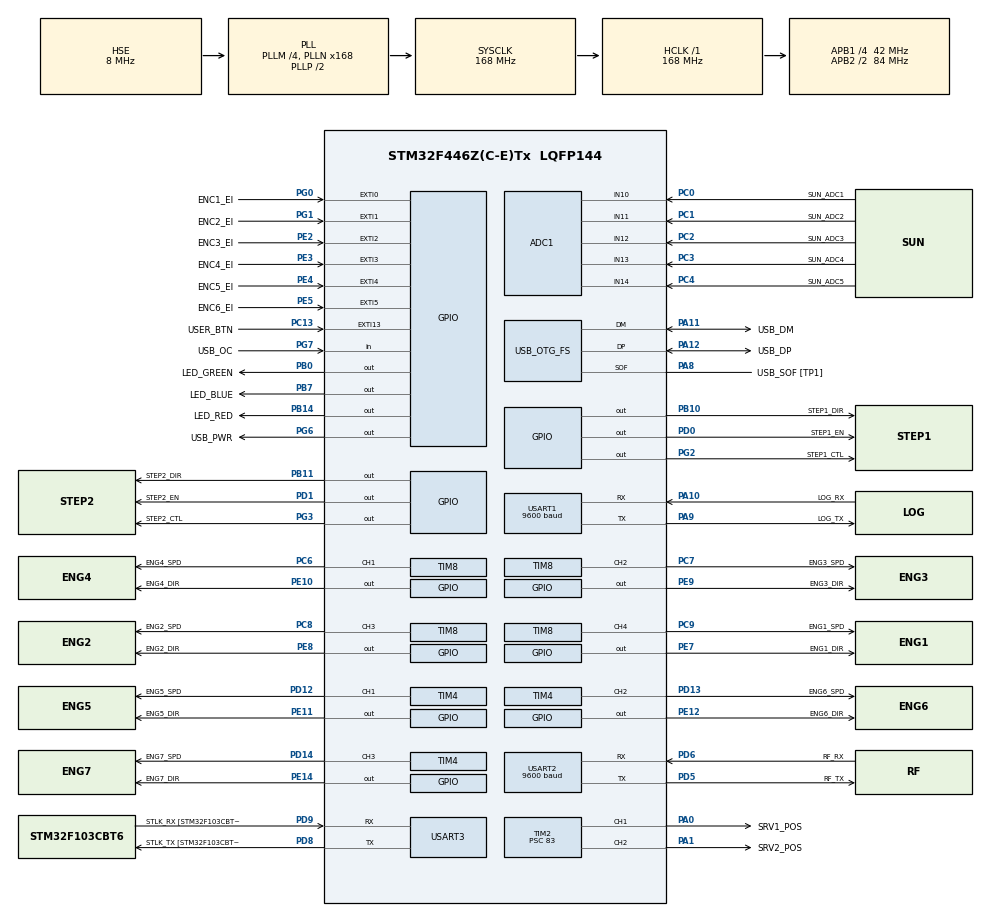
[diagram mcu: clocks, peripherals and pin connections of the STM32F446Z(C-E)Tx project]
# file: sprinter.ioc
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ADC1.Channel-0\#ChannelRegularConversion=ADC_CHANNEL_10
ADC1.ContinuousConvMode=ENABLE
ADC1.NbrOfConversion=1
ADC1.NbrOfConversionFlag=1
ADC1.Rank-0\#ChannelRegularConversion=1
ADC1.SamplingTime-0\#ChannelRegularConversion=ADC_SAMPLETIME_3CYCLES
ADC1.master=1
Mcu.Family=STM32F4
Mcu.Name=STM32F446Z(C-E)Tx
Mcu.Package=LQFP144
NVIC.EXTI0_IRQn=true\:0\:0\:false\:false\:true\:true\:true
NVIC.EXTI15_10_IRQn=true\:0\:0\:false\:false\:true\:true\:true
NVIC.EXTI1_IRQn=true\:0\:0\:false\:false\:true\:true\:true
NVIC.EXTI2_IRQn=true\:0\:0\:false\:false\:true\:true\:true
NVIC.EXTI3_IRQn=true\:0\:0\:false\:false\:true\:true\:true
NVIC.EXTI4_IRQn=true\:0\:0\:false\:false\:true\:true\:true
NVIC.EXTI9_5_IRQn=true\:0\:0\:false\:false\:true\:true\:true
NVIC.PriorityGroup=NVIC_PRIORITYGROUP_4
NVIC.USART1_IRQn=true\:0\:0\:false\:false\:true\:true\:true
NVIC.USART2_IRQn=true\:0\:0\:false\:false\:true\:true\:true
PA0-WKUP.GPIO_Label=SRV1_POS
PA0-WKUP.Signal=S_TIM2_CH1_ETR
PA1.GPIO_Label=SRV2_POS
PA1.Signal=S_TIM2_CH2
PA10.GPIO_Label=LOG_RX
PA10.Mode=Asynchronous
PA10.Signal=USART1_RX
PA11.GPIO_Label=USB_DM
PA11.Mode=Device_Only
PA11.Signal=USB_OTG_FS_DM
PA12.GPIO_Label=USB_DP
PA12.Mode=Device_Only
PA12.Signal=USB_OTG_FS_DP
PA13.GPIO_Label=TMS
PA13.Mode=Serial_Wire
PA13.Signal=SYS_JTMS-SWDIO
PA14.GPIO_Label=TCK
PA14.Mode=Serial_Wire
PA14.Signal=SYS_JTCK-SWCLK
PA8.GPIO_Label=USB_SOF [TP1]
PA8.Mode=Activate_SOF_FS
PA8.Signal=USB_OTG_FS_SOF
PA9.GPIO_Label=LOG_TX
PA9.Mode=Asynchronous
PA9.Signal=USART1_TX
PB0.GPIO_Label=LED_GREEN
PB0.Signal=GPIO_Output
PB10.GPIO_Label=STEP1_DIR
PB10.Signal=GPIO_Output
PB11.GPIO_Label=STEP2_DIR
PB11.Signal=GPIO_Output
PB14.GPIO_Label=LED_RED
PB14.Signal=GPIO_Output
PB7.GPIO_Label=LED_BLUE
PB7.Signal=GPIO_Output
PC0.GPIO_Label=SUN_ADC1
PC0.Signal=ADCx_IN10
PC1.GPIO_Label=SUN_ADC2
PC1.Signal=ADCx_IN11
PC13.GPIO_Label=USER_BTN
PC13.Signal=GPXTI13
PC14-OSC32_IN.GPIO_Label=OSC32_IN
PC14-OSC32_IN.Mode=LSE-External-Oscillator
PC14-OSC32_IN.Signal=RCC_OSC32_IN
PC15-OSC32_OUT.GPIO_Label=OSC32_OUT
PC15-OSC32_OUT.Mode=LSE-External-Oscillator
PC15-OSC32_OUT.Signal=RCC_OSC32_OUT
PC2.GPIO_Label=SUN_ADC3
PC2.Signal=ADCx_IN12
PC3.GPIO_Label=SUN_ADC4
PC3.Signal=ADCx_IN13
PC4.GPIO_Label=SUN_ADC5
PC4.Signal=ADCx_IN14
PC6.GPIO_Label=ENG4_SPD
PC6.Signal=S_TIM8_CH1
PC7.GPIO_Label=ENG3_SPD
PC7.Signal=S_TIM8_CH2
PC8.GPIO_Label=ENG2_SPD
PC8.Signal=S_TIM8_CH3
PC9.GPIO_Label=ENG1_SPD
PC9.Signal=S_TIM8_CH4
PD0.GPIO_Label=STEP1_EN
PD0.Signal=GPIO_Output
PD1.GPIO_Label=STEP2_EN
PD1.Signal=GPIO_Output
PD12.GPIO_Label=ENG5_SPD
PD12.Signal=S_TIM4_CH1
PD13.GPIO_Label=ENG6_SPD
PD13.Signal=S_TIM4_CH2
PD14.GPIO_Label=ENG7_SPD
PD14.Signal=S_TIM4_CH3
PD5.GPIO_Label=RF_TX
PD5.Mode=Asynchronous
PD5.Signal=USART2_TX
PD6.GPIO_Label=RF_RX
PD6.Mode=Asynchronous
PD6.Signal=USART2_RX
PD8.GPIO_Label=STLK_TX [STM32F103CBT6_PA3]
PD8.Mode=Asynchronous
PD8.Signal=USART3_TX
PD9.GPIO_Label=STLK_RX [STM32F103CBT6_PA2]
PD9.Mode=Asynchronous
PD9.Signal=USART3_RX
PE10.GPIO_Label=ENG4_DIR
PE10.Signal=GPIO_Output
PE11.GPIO_Label=ENG5_DIR
PE11.Signal=GPIO_Output
PE12.GPIO_Label=ENG6_DIR
PE12.Signal=GPIO_Output
PE14.GPIO_Label=ENG7_DIR
PE14.Signal=GPIO_Output
PE2.GPIO_Label=ENC3_EI
PE2.GPIO_ModeDefaultEXTI=GPIO_MODE_IT_RISING_FALLING
PE2.GPIO_PuPd=GPIO_PULLDOWN
PE2.Signal=GPXTI2
PE3.GPIO_Label=ENC4_EI
PE3.GPIO_ModeDefaultEXTI=GPIO_MODE_IT_RISING_FALLING
PE3.GPIO_PuPd=GPIO_PULLDOWN
PE3.Signal=GPXTI3
PE4.GPIO_Label=ENC5_EI
PE4.GPIO_ModeDefaultEXTI=GPIO_MODE_IT_RISING_FALLING
PE4.GPIO_PuPd=GPIO_PULLDOWN
PE4.Signal=GPXTI4
PE5.GPIO_Label=ENC6_EI
PE5.GPIO_ModeDefaultEXTI=GPIO_MODE_IT_RISING_FALLING
PE5.GPIO_PuPd=GPIO_PULLDOWN
PE5.Signal=GPXTI5
PE7.GPIO_Label=ENG1_DIR
PE7.Signal=GPIO_Output
PE8.GPIO_Label=ENG2_DIR
PE8.Signal=GPIO_Output
PE9.GPIO_Label=ENG3_DIR
PE9.Signal=GPIO_Output
PG0.GPIO_Label=ENC1_EI
PG0.GPIO_ModeDefaultEXTI=GPIO_MODE_IT_RISING_FALLING
PG0.GPIO_PuPd=GPIO_PULLDOWN
PG0.Signal=GPXTI0
PG1.GPIO_Label=ENC2_EI
PG1.GPIO_ModeDefaultEXTI=GPIO_MODE_IT_RISING_FALLING
PG1.GPIO_PuPd=GPIO_PULLDOWN
PG1.Signal=GPXTI1
PG2.GPIO_Label=STEP1_CTL
PG2.Signal=GPIO_Output
PG3.GPIO_Label=STEP2_CTL
PG3.Signal=GPIO_Output
PG6.GPIO_Label=USB_PWR
PG6.Signal=GPIO_Output
PG7.GPIO_Label=USB_OC
PG7.Signal=GPIO_Input
PH0-OSC_IN.GPIO_Label=MCO [STM32F103CBT6_PA8]
PH0-OSC_IN.Mode=HSE-External-Clock-Source
PH0-OSC_IN.Signal=RCC_OSC_IN
PH1-OSC_OUT.GPIO_Label=OSC_OUT
PH1-OSC_OUT.Mode=HSE-External-Clock-Source
PH1-OSC_OUT.Signal=RCC_OSC_OUT
ProjectManager.HeapSize=0x200
ProjectManager.StackSize=0x400
ProjectManager.TargetToolchain=SW4STM32
RCC.48MHZClocksFreq_Value=24000000
RCC.AHBFreq_Value=168000000
RCC.APB1CLKDivider=RCC_HCLK_DIV4
RCC.APB1Freq_Value=42000000
RCC.APB1TimFreq_Value=84000000
RCC.APB2CLKDivider=RCC_HCLK_DIV2
RCC.APB2Freq_Value=84000000
RCC.APB2TimFreq_Value=168000000
RCC.CortexFreq_Value=168000000
RCC.HCLKFreq_Value=168000000
RCC.HSE_VALUE=8000000
RCC.HSI_VALUE=16000000
RCC.PLLM=4
RCC.PLLMUL=RCC_PLL_MUL9
RCC.PLLN=168
RCC.PLLQ=7
RCC.PRESCALERUSB=RCC_USBCLKSOURCE_PLL_DIV1_5
RCC.SYSCLKFreq_VALUE=168000000
RCC.SYSCLKSource=RCC_SYSCLKSOURCE_PLLCLK
RCC.SYSCLKSourceVirtual=RCC_SYSCLKSOURCE_PLLCLK
RCC.USBFreq_Value=48000000
RCC.VCOOutputFreq_Value=336000000
SH.ADCx_IN10.0=ADC1_IN10,IN10
SH.ADCx_IN11.0=ADC1_IN11,IN11
SH.ADCx_IN12.0=ADC1_IN12,IN12
SH.ADCx_IN13.0=ADC1_IN13,IN13
SH.ADCx_IN14.0=ADC1_IN14,IN14
SH.S_TIM2_CH1_ETR.0=TIM2_CH1,PWM Generation1 CH1
SH.S_TIM2_CH2.0=TIM2_CH2,PWM Generation2 CH2
SH.S_TIM4_CH1.0=TIM4_CH1,PWM Generation1 CH1
SH.S_TIM4_CH2.0=TIM4_CH2,PWM Generation2 CH2
SH.S_TIM4_CH3.0=TIM4_CH3,PWM Generation3 CH3
SH.S_TIM8_CH1.0=TIM8_CH1,PWM Generation1 CH1
SH.S_TIM8_CH2.0=TIM8_CH2,PWM Generation2 CH2
SH.S_TIM8_CH3.0=TIM8_CH3,PWM Generation3 CH3
SH.S_TIM8_CH4.0=TIM8_CH4,PWM Generation4 CH4
TIM2.Channel-PWM\ Generation1\ CH1=TIM_CHANNEL_1
TIM2.Channel-PWM\ Generation2\ CH2=TIM_CHANNEL_2
TIM2.OCMode_PWM-PWM\ Generation1\ CH1=TIM_OCMODE_PWM2
TIM2.OCMode_PWM-PWM\ Generation2\ CH2=TIM_OCMODE_PWM2
TIM2.OCPolarity_2=TIM_OCPOLARITY_LOW
TIM2.Period=19999
TIM2.Prescaler=83
TIM2.Pulse-PWM\ Generation1\ CH1=3360000
TIM2.Pulse-PWM\ Generation2\ CH2=3360000
TIM4.Channel-PWM\ Generation1\ CH1=TIM_CHANNEL_1
TIM4.Channel-PWM\ Generation2\ CH2=TIM_CHANNEL_2
TIM4.Channel-PWM\ Generation3\ CH3=TIM_CHANNEL_3
TIM4.OCMode_PWM-PWM\ Generation1\ CH1=TIM_OCMODE_PWM2
TIM4.OCMode_PWM-PWM\ Generation2\ CH2=TIM_OCMODE_PWM2
TIM4.OCMode_PWM-PWM\ Generation3\ CH3=TIM_OCMODE_PWM2
TIM4.OCPolarity_1=TIM_OCPOLARITY_LOW
TIM4.OCPolarity_2=TIM_OCPOLARITY_LOW
TIM4.OCPolarity_3=TIM_OCPOLARITY_LOW
TIM4.Period=99
TIM4.Prescaler=1049
TIM4.Pulse-PWM\ Generation1\ CH1=210000
TIM4.Pulse-PWM\ Generation2\ CH2=210000
TIM4.Pulse-PWM\ Generation3\ CH3=210000
TIM8.Channel-PWM\ Generation1\ CH1=TIM_CHANNEL_1
TIM8.Channel-PWM\ Generation2\ CH2=TIM_CHANNEL_2
TIM8.Channel-PWM\ Generation3\ CH3=TIM_CHANNEL_3
TIM8.Channel-PWM\ Generation4\ CH4=TIM_CHANNEL_4
TIM8.OCIdleState_1=TIM_OCIDLESTATE_SET
TIM8.OCIdleState_2=TIM_OCIDLESTATE_SET
TIM8.OCIdleState_3=TIM_OCIDLESTATE_SET
TIM8.OCIdleState_4=TIM_OCIDLESTATE_SET
TIM8.OCMode_PWM-PWM\ Generation1\ CH1=TIM_OCMODE_PWM2
TIM8.OCMode_PWM-PWM\ Generation2\ CH2=TIM_OCMODE_PWM2
TIM8.OCMode_PWM-PWM\ Generation3\ CH3=TIM_OCMODE_PWM2
TIM8.OCMode_PWM-PWM\ Generation4\ CH4=TIM_OCMODE_PWM2
TIM8.OCPolarity_1=TIM_OCPOLARITY_LOW
TIM8.OCPolarity_2=TIM_OCPOLARITY_LOW
TIM8.OCPolarity_3=TIM_OCPOLARITY_LOW
TIM8.OCPolarity_4=TIM_OCPOLARITY_LOW
TIM8.Period=99
TIM8.Prescaler=2099
TIM8.Pulse-PWM\ Generation1\ CH1=210000
TIM8.Pulse-PWM\ Generation2\ CH2=210000
TIM8.Pulse-PWM\ Generation3\ CH3=210000
TIM8.Pulse-PWM\ Generation4\ CH4=210000
USART1.BaudRate=9600
USART1.VirtualMode=VM_ASYNC
USART2.BaudRate=9600
USART2.VirtualMode=VM_ASYNC
USART3.VirtualMode=VM_ASYNC
USB_OTG_FS.VirtualMode=Device_Only
VP_TIM2_VS_ClockSourceINT.Mode=Internal
VP_TIM4_VS_ClockSourceINT.Mode=Internal
VP_TIM8_VS_ClockSourceINT.Mode=Internal
board=NUCLEO-F446ZE

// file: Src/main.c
/* USER CODE BEGIN Header */
/**
  ******************************************************************************
  * @file           : main.c
  * @brief          : Main program body
  ******************************************************************************
  * @attention
  *
  * <h2><center>&copy; Copyright (c) 2019 STMicroelectronics.
  * All rights reserved.</center></h2>
  *
  * This software component is licensed by ST under BSD 3-Clause license,
  * the "License"; You may not use this file except in compliance with the
  * License. You may obtain a copy of the License at:
  *                        opensource.org/licenses/BSD-3-Clause
  *
  ******************************************************************************
  */
/* USER CODE END Header */

#include "main.h"

/* USER CODE BEGIN Includes */
#include "sprinter/run.h"
/* USER CODE END Includes */

ADC_HandleTypeDef hadc1;

TIM_HandleTypeDef htim2;
TIM_HandleTypeDef htim4;
TIM_HandleTypeDef htim8;

UART_HandleTypeDef huart1;
UART_HandleTypeDef huart2;
UART_HandleTypeDef huart3;

PCD_HandleTypeDef hpcd_USB_OTG_FS;

void SystemClock_Config(void);
static void MX_GPIO_Init(void);
static void MX_USART3_UART_Init(void);
static void MX_USB_OTG_FS_PCD_Init(void);
static void MX_USART2_UART_Init(void);
static void MX_TIM8_Init(void);
static void MX_USART1_UART_Init(void);
static void MX_TIM4_Init(void);
static void MX_ADC1_Init(void);
static void MX_TIM2_Init(void);

int main(void)
{

  /* MCU Configuration--------------------------------------------------------*/

  /* Reset of all peripherals, Initializes the Flash interface and the Systick. */
  HAL_Init();

  /* Configure the system clock */
  SystemClock_Config();

  /* Initialize all configured peripherals */
  MX_GPIO_Init();
  MX_USART3_UART_Init();
  MX_USB_OTG_FS_PCD_Init();
  MX_USART2_UART_Init();
  MX_TIM8_Init();
  MX_USART1_UART_Init();
  MX_TIM4_Init();
  MX_ADC1_Init();
  MX_TIM2_Init();

  /* Infinite loop */
  /* USER CODE BEGIN WHILE */

  // no return
  run();

    /* USER CODE END WHILE */

}

void SystemClock_Config(void)
{
  RCC_OscInitTypeDef RCC_OscInitStruct = {0};
  RCC_ClkInitTypeDef RCC_ClkInitStruct = {0};
  RCC_PeriphCLKInitTypeDef PeriphClkInitStruct = {0};

  /** Configure the main internal regulator output voltage
  */
  __HAL_RCC_PWR_CLK_ENABLE();
  __HAL_PWR_VOLTAGESCALING_CONFIG(PWR_REGULATOR_VOLTAGE_SCALE1);
  /** Initializes the CPU, AHB and APB busses clocks
  */
  RCC_OscInitStruct.OscillatorType = RCC_OSCILLATORTYPE_HSE;
  RCC_OscInitStruct.HSEState = RCC_HSE_BYPASS;
  RCC_OscInitStruct.PLL.PLLState = RCC_PLL_ON;
  RCC_OscInitStruct.PLL.PLLSource = RCC_PLLSOURCE_HSE;
  RCC_OscInitStruct.PLL.PLLM = 4;
  RCC_OscInitStruct.PLL.PLLN = 168;
  RCC_OscInitStruct.PLL.PLLP = RCC_PLLP_DIV2;
  RCC_OscInitStruct.PLL.PLLQ = 7;
  RCC_OscInitStruct.PLL.PLLR = 2;
  if (HAL_RCC_OscConfig(&RCC_OscInitStruct) != HAL_OK)
  {
    Error_Handler();
  }
  /** Initializes the CPU, AHB and APB busses clocks
  */
  RCC_ClkInitStruct.ClockType = RCC_CLOCKTYPE_HCLK|RCC_CLOCKTYPE_SYSCLK
                              |RCC_CLOCKTYPE_PCLK1|RCC_CLOCKTYPE_PCLK2;
  RCC_ClkInitStruct.SYSCLKSource = RCC_SYSCLKSOURCE_PLLCLK;
  RCC_ClkInitStruct.AHBCLKDivider = RCC_SYSCLK_DIV1;
  RCC_ClkInitStruct.APB1CLKDivider = RCC_HCLK_DIV4;
  RCC_ClkInitStruct.APB2CLKDivider = RCC_HCLK_DIV2;

  if (HAL_RCC_ClockConfig(&RCC_ClkInitStruct, FLASH_LATENCY_5) != HAL_OK)
  {
    Error_Handler();
  }
  PeriphClkInitStruct.PeriphClockSelection = RCC_PERIPHCLK_CLK48;
  PeriphClkInitStruct.Clk48ClockSelection = RCC_CLK48CLKSOURCE_PLLQ;
  if (HAL_RCCEx_PeriphCLKConfig(&PeriphClkInitStruct) != HAL_OK)
  {
    Error_Handler();
  }
}

static void MX_ADC1_Init(void)
{

  ADC_ChannelConfTypeDef sConfig = {0};

  /** Configure the global features of the ADC (Clock, Resolution, Data Alignment and number of conversion)
  */
  hadc1.Instance = ADC1;
  hadc1.Init.ClockPrescaler = ADC_CLOCK_SYNC_PCLK_DIV4;
  hadc1.Init.Resolution = ADC_RESOLUTION_12B;
  hadc1.Init.ScanConvMode = DISABLE;
  hadc1.Init.ContinuousConvMode = ENABLE;
  hadc1.Init.DiscontinuousConvMode = DISABLE;
  hadc1.Init.ExternalTrigConvEdge = ADC_EXTERNALTRIGCONVEDGE_NONE;
  hadc1.Init.ExternalTrigConv = ADC_SOFTWARE_START;
  hadc1.Init.DataAlign = ADC_DATAALIGN_RIGHT;
  hadc1.Init.NbrOfConversion = 1;
  hadc1.Init.DMAContinuousRequests = DISABLE;
  hadc1.Init.EOCSelection = ADC_EOC_SINGLE_CONV;
  if (HAL_ADC_Init(&hadc1) != HAL_OK)
  {
    Error_Handler();
  }
  /** Configure for the selected ADC regular channel its corresponding rank in the sequencer and its sample time.
  */
  sConfig.Channel = ADC_CHANNEL_10;
  sConfig.Rank = 1;
  sConfig.SamplingTime = ADC_SAMPLETIME_3CYCLES;
  if (HAL_ADC_ConfigChannel(&hadc1, &sConfig) != HAL_OK)
  {
    Error_Handler();
  }

}

static void MX_TIM2_Init(void)
{

  TIM_ClockConfigTypeDef sClockSourceConfig = {0};
  TIM_MasterConfigTypeDef sMasterConfig = {0};
  TIM_OC_InitTypeDef sConfigOC = {0};

  /* USER CODE BEGIN TIM2_Init 1 */

  sConfigOC.OCNPolarity = TIM_OCNPOLARITY_HIGH;
  sConfigOC.OCIdleState = TIM_OCIDLESTATE_SET;
  sConfigOC.OCNIdleState = TIM_OCNIDLESTATE_RESET;

  /* USER CODE END TIM2_Init 1 */
  htim2.Instance = TIM2;
  htim2.Init.Prescaler = 83;
  htim2.Init.CounterMode = TIM_COUNTERMODE_UP;
  htim2.Init.Period = 19999;
  htim2.Init.ClockDivision = TIM_CLOCKDIVISION_DIV1;
  htim2.Init.AutoReloadPreload = TIM_AUTORELOAD_PRELOAD_DISABLE;
  if (HAL_TIM_Base_Init(&htim2) != HAL_OK)
  {
    Error_Handler();
  }
  sClockSourceConfig.ClockSource = TIM_CLOCKSOURCE_INTERNAL;
  if (HAL_TIM_ConfigClockSource(&htim2, &sClockSourceConfig) != HAL_OK)
  {
    Error_Handler();
  }
  if (HAL_TIM_PWM_Init(&htim2) != HAL_OK)
  {
    Error_Handler();
  }
  sMasterConfig.MasterOutputTrigger = TIM_TRGO_RESET;
  sMasterConfig.MasterSlaveMode = TIM_MASTERSLAVEMODE_DISABLE;
  if (HAL_TIMEx_MasterConfigSynchronization(&htim2, &sMasterConfig) != HAL_OK)
  {
    Error_Handler();
  }
  sConfigOC.OCMode = TIM_OCMODE_PWM2;
  sConfigOC.Pulse = 3360000;
  sConfigOC.OCPolarity = TIM_OCPOLARITY_HIGH;
  sConfigOC.OCFastMode = TIM_OCFAST_DISABLE;
  if (HAL_TIM_PWM_ConfigChannel(&htim2, &sConfigOC, TIM_CHANNEL_1) != HAL_OK)
  {
    Error_Handler();
  }
  sConfigOC.OCPolarity = TIM_OCPOLARITY_LOW;
  if (HAL_TIM_PWM_ConfigChannel(&htim2, &sConfigOC, TIM_CHANNEL_2) != HAL_OK)
  {
    Error_Handler();
  }
  HAL_TIM_MspPostInit(&htim2);

}

static void MX_TIM4_Init(void)
{

  TIM_ClockConfigTypeDef sClockSourceConfig = {0};
  TIM_MasterConfigTypeDef sMasterConfig = {0};
  TIM_OC_InitTypeDef sConfigOC = {0};

  /* USER CODE BEGIN TIM4_Init 1 */

  sConfigOC.OCNPolarity = TIM_OCNPOLARITY_HIGH;
  sConfigOC.OCIdleState = TIM_OCIDLESTATE_SET;
  sConfigOC.OCNIdleState = TIM_OCNIDLESTATE_RESET;

  /* USER CODE END TIM4_Init 1 */
  htim4.Instance = TIM4;
  htim4.Init.Prescaler = 1049;
  htim4.Init.CounterMode = TIM_COUNTERMODE_UP;
  htim4.Init.Period = 99;
  htim4.Init.ClockDivision = TIM_CLOCKDIVISION_DIV1;
  htim4.Init.AutoReloadPreload = TIM_AUTORELOAD_PRELOAD_DISABLE;
  if (HAL_TIM_Base_Init(&htim4) != HAL_OK)
  {
    Error_Handler();
  }
  sClockSourceConfig.ClockSource = TIM_CLOCKSOURCE_INTERNAL;
  if (HAL_TIM_ConfigClockSource(&htim4, &sClockSourceConfig) != HAL_OK)
  {
    Error_Handler();
  }
  if (HAL_TIM_PWM_Init(&htim4) != HAL_OK)
  {
    Error_Handler();
  }
  sMasterConfig.MasterOutputTrigger = TIM_TRGO_RESET;
  sMasterConfig.MasterSlaveMode = TIM_MASTERSLAVEMODE_DISABLE;
  if (HAL_TIMEx_MasterConfigSynchronization(&htim4, &sMasterConfig) != HAL_OK)
  {
    Error_Handler();
  }
  sConfigOC.OCMode = TIM_OCMODE_PWM2;
  sConfigOC.Pulse = 210000;
  sConfigOC.OCPolarity = TIM_OCPOLARITY_LOW;
  sConfigOC.OCFastMode = TIM_OCFAST_DISABLE;
  if (HAL_TIM_PWM_ConfigChannel(&htim4, &sConfigOC, TIM_CHANNEL_1) != HAL_OK)
  {
    Error_Handler();
  }
  if (HAL_TIM_PWM_ConfigChannel(&htim4, &sConfigOC, TIM_CHANNEL_2) != HAL_OK)
  {
    Error_Handler();
  }
  if (HAL_TIM_PWM_ConfigChannel(&htim4, &sConfigOC, TIM_CHANNEL_3) != HAL_OK)
  {
    Error_Handler();
  }
  /* USER CODE BEGIN TIM4_Init 2 */

	htim2.Instance->CCR1 = htim2.Instance->CCR2 = htim2.Instance->CCR3 = htim2.Instance->CCR4 = 0;
	htim4.Instance->CCR1 = htim4.Instance->CCR2 = htim4.Instance->CCR3 = htim4.Instance->CCR4 = 0;
	htim8.Instance->CCR1 = htim8.Instance->CCR2 = htim8.Instance->CCR3 = htim8.Instance->CCR4 = 0;

	/* USER CODE END TIM4_Init 2 */
  HAL_TIM_MspPostInit(&htim4);

}

static void MX_TIM8_Init(void)
{

  TIM_ClockConfigTypeDef sClockSourceConfig = {0};
  TIM_MasterConfigTypeDef sMasterConfig = {0};
  TIM_OC_InitTypeDef sConfigOC = {0};
  TIM_BreakDeadTimeConfigTypeDef sBreakDeadTimeConfig = {0};

  htim8.Instance = TIM8;
  htim8.Init.Prescaler = 2099;
  htim8.Init.CounterMode = TIM_COUNTERMODE_UP;
  htim8.Init.Period = 99;
  htim8.Init.ClockDivision = TIM_CLOCKDIVISION_DIV1;
  htim8.Init.RepetitionCounter = 0;
  htim8.Init.AutoReloadPreload = TIM_AUTORELOAD_PRELOAD_DISABLE;
  if (HAL_TIM_Base_Init(&htim8) != HAL_OK)
  {
    Error_Handler();
  }
  sClockSourceConfig.ClockSource = TIM_CLOCKSOURCE_INTERNAL;
  if (HAL_TIM_ConfigClockSource(&htim8, &sClockSourceConfig) != HAL_OK)
  {
    Error_Handler();
  }
  if (HAL_TIM_PWM_Init(&htim8) != HAL_OK)
  {
    Error_Handler();
  }
  sMasterConfig.MasterOutputTrigger = TIM_TRGO_RESET;
  sMasterConfig.MasterSlaveMode = TIM_MASTERSLAVEMODE_DISABLE;
  if (HAL_TIMEx_MasterConfigSynchronization(&htim8, &sMasterConfig) != HAL_OK)
  {
    Error_Handler();
  }
  sConfigOC.OCMode = TIM_OCMODE_PWM2;
  sConfigOC.Pulse = 210000;
  sConfigOC.OCPolarity = TIM_OCPOLARITY_LOW;
  sConfigOC.OCNPolarity = TIM_OCNPOLARITY_HIGH;
  sConfigOC.OCFastMode = TIM_OCFAST_DISABLE;
  sConfigOC.OCIdleState = TIM_OCIDLESTATE_SET;
  sConfigOC.OCNIdleState = TIM_OCNIDLESTATE_RESET;
  if (HAL_TIM_PWM_ConfigChannel(&htim8, &sConfigOC, TIM_CHANNEL_1) != HAL_OK)
  {
    Error_Handler();
  }
  if (HAL_TIM_PWM_ConfigChannel(&htim8, &sConfigOC, TIM_CHANNEL_2) != HAL_OK)
  {
    Error_Handler();
  }
  if (HAL_TIM_PWM_ConfigChannel(&htim8, &sConfigOC, TIM_CHANNEL_3) != HAL_OK)
  {
    Error_Handler();
  }
  if (HAL_TIM_PWM_ConfigChannel(&htim8, &sConfigOC, TIM_CHANNEL_4) != HAL_OK)
  {
    Error_Handler();
  }
  sBreakDeadTimeConfig.OffStateRunMode = TIM_OSSR_DISABLE;
  sBreakDeadTimeConfig.OffStateIDLEMode = TIM_OSSI_DISABLE;
  sBreakDeadTimeConfig.LockLevel = TIM_LOCKLEVEL_OFF;
  sBreakDeadTimeConfig.DeadTime = 0;
  sBreakDeadTimeConfig.BreakState = TIM_BREAK_DISABLE;
  sBreakDeadTimeConfig.BreakPolarity = TIM_BREAKPOLARITY_HIGH;
  sBreakDeadTimeConfig.AutomaticOutput = TIM_AUTOMATICOUTPUT_DISABLE;
  if (HAL_TIMEx_ConfigBreakDeadTime(&htim8, &sBreakDeadTimeConfig) != HAL_OK)
  {
    Error_Handler();
  }
  HAL_TIM_MspPostInit(&htim8);

}

static void MX_USART1_UART_Init(void)
{

  huart1.Instance = USART1;
  huart1.Init.BaudRate = 9600;
  huart1.Init.WordLength = UART_WORDLENGTH_8B;
  huart1.Init.StopBits = UART_STOPBITS_1;
  huart1.Init.Parity = UART_PARITY_NONE;
  huart1.Init.Mode = UART_MODE_TX_RX;
  huart1.Init.HwFlowCtl = UART_HWCONTROL_NONE;
  huart1.Init.OverSampling = UART_OVERSAMPLING_16;
  if (HAL_UART_Init(&huart1) != HAL_OK)
  {
    Error_Handler();
  }

}

static void MX_USART2_UART_Init(void)
{

  huart2.Instance = USART2;
  huart2.Init.BaudRate = 9600;
  huart2.Init.WordLength = UART_WORDLENGTH_8B;
  huart2.Init.StopBits = UART_STOPBITS_1;
  huart2.Init.Parity = UART_PARITY_NONE;
  huart2.Init.Mode = UART_MODE_TX_RX;
  huart2.Init.HwFlowCtl = UART_HWCONTROL_NONE;
  huart2.Init.OverSampling = UART_OVERSAMPLING_16;
  if (HAL_UART_Init(&huart2) != HAL_OK)
  {
    Error_Handler();
  }

}

static void MX_USART3_UART_Init(void)
{

  huart3.Instance = USART3;
  huart3.Init.BaudRate = 115200;
  huart3.Init.WordLength = UART_WORDLENGTH_8B;
  huart3.Init.StopBits = UART_STOPBITS_1;
  huart3.Init.Parity = UART_PARITY_NONE;
  huart3.Init.Mode = UART_MODE_TX_RX;
  huart3.Init.HwFlowCtl = UART_HWCONTROL_NONE;
  huart3.Init.OverSampling = UART_OVERSAMPLING_16;
  if (HAL_UART_Init(&huart3) != HAL_OK)
  {
    Error_Handler();
  }

}

static void MX_USB_OTG_FS_PCD_Init(void)
{

  hpcd_USB_OTG_FS.Instance = USB_OTG_FS;
  hpcd_USB_OTG_FS.Init.dev_endpoints = 6;
  hpcd_USB_OTG_FS.Init.speed = PCD_SPEED_FULL;
  hpcd_USB_OTG_FS.Init.dma_enable = DISABLE;
  hpcd_USB_OTG_FS.Init.phy_itface = PCD_PHY_EMBEDDED;
  hpcd_USB_OTG_FS.Init.Sof_enable = ENABLE;
  hpcd_USB_OTG_FS.Init.low_power_enable = DISABLE;
  hpcd_USB_OTG_FS.Init.lpm_enable = DISABLE;
  hpcd_USB_OTG_FS.Init.vbus_sensing_enable = DISABLE;
  hpcd_USB_OTG_FS.Init.use_dedicated_ep1 = DISABLE;
  if (HAL_PCD_Init(&hpcd_USB_OTG_FS) != HAL_OK)
  {
    Error_Handler();
  }

}

static void MX_GPIO_Init(void)
{
  GPIO_InitTypeDef GPIO_InitStruct = {0};

  /* GPIO Ports Clock Enable */
  __HAL_RCC_GPIOE_CLK_ENABLE();
  __HAL_RCC_GPIOC_CLK_ENABLE();
  __HAL_RCC_GPIOH_CLK_ENABLE();
  __HAL_RCC_GPIOA_CLK_ENABLE();
  __HAL_RCC_GPIOB_CLK_ENABLE();
  __HAL_RCC_GPIOG_CLK_ENABLE();
  __HAL_RCC_GPIOD_CLK_ENABLE();

  /*Configure GPIO pin Output Level */
  HAL_GPIO_WritePin(GPIOB, LED_GREEN_Pin|STEP1_DIR_Pin|STEP2_DIR_Pin|LED_RED_Pin
                          |LED_BLUE_Pin, GPIO_PIN_RESET);

  /*Configure GPIO pin Output Level */
  HAL_GPIO_WritePin(GPIOE, ENG1_DIR_Pin|ENG2_DIR_Pin|ENG3_DIR_Pin|ENG4_DIR_Pin
                          |ENG5_DIR_Pin|ENG6_DIR_Pin|ENG7_DIR_Pin, GPIO_PIN_RESET);

  /*Configure GPIO pin Output Level */
  HAL_GPIO_WritePin(GPIOG, STEP1_CTL_Pin|STEP2_CTL_Pin|USB_PWR_Pin, GPIO_PIN_RESET);

  /*Configure GPIO pin Output Level */
  HAL_GPIO_WritePin(GPIOD, STEP1_EN_Pin|STEP2_EN_Pin, GPIO_PIN_RESET);

  /*Configure GPIO pins : ENC3_EI_Pin ENC4_EI_Pin ENC5_EI_Pin ENC6_EI_Pin */
  GPIO_InitStruct.Pin = ENC3_EI_Pin|ENC4_EI_Pin|ENC5_EI_Pin|ENC6_EI_Pin;
  GPIO_InitStruct.Mode = GPIO_MODE_IT_RISING_FALLING;
  GPIO_InitStruct.Pull = GPIO_PULLDOWN;
  HAL_GPIO_Init(GPIOE, &GPIO_InitStruct);

  /*Configure GPIO pin : USER_BTN_Pin */
  GPIO_InitStruct.Pin = USER_BTN_Pin;
  GPIO_InitStruct.Mode = GPIO_MODE_IT_RISING;
  GPIO_InitStruct.Pull = GPIO_NOPULL;
  HAL_GPIO_Init(USER_BTN_GPIO_Port, &GPIO_InitStruct);

  /*Configure GPIO pins : LED_GREEN_Pin STEP1_DIR_Pin STEP2_DIR_Pin LED_RED_Pin
                           LED_BLUE_Pin */
  GPIO_InitStruct.Pin = LED_GREEN_Pin|STEP1_DIR_Pin|STEP2_DIR_Pin|LED_RED_Pin
                          |LED_BLUE_Pin;
  GPIO_InitStruct.Mode = GPIO_MODE_OUTPUT_PP;
  GPIO_InitStruct.Pull = GPIO_NOPULL;
  GPIO_InitStruct.Speed = GPIO_SPEED_FREQ_LOW;
  HAL_GPIO_Init(GPIOB, &GPIO_InitStruct);

  /*Configure GPIO pins : ENC1_EI_Pin ENC2_EI_Pin */
  GPIO_InitStruct.Pin = ENC1_EI_Pin|ENC2_EI_Pin;
  GPIO_InitStruct.Mode = GPIO_MODE_IT_RISING_FALLING;
  GPIO_InitStruct.Pull = GPIO_PULLDOWN;
  HAL_GPIO_Init(GPIOG, &GPIO_InitStruct);

  /*Configure GPIO pins : ENG1_DIR_Pin ENG2_DIR_Pin ENG3_DIR_Pin ENG4_DIR_Pin
                           ENG5_DIR_Pin ENG6_DIR_Pin ENG7_DIR_Pin */
  GPIO_InitStruct.Pin = ENG1_DIR_Pin|ENG2_DIR_Pin|ENG3_DIR_Pin|ENG4_DIR_Pin
                          |ENG5_DIR_Pin|ENG6_DIR_Pin|ENG7_DIR_Pin;
  GPIO_InitStruct.Mode = GPIO_MODE_OUTPUT_PP;
  GPIO_InitStruct.Pull = GPIO_NOPULL;
  GPIO_InitStruct.Speed = GPIO_SPEED_FREQ_LOW;
  HAL_GPIO_Init(GPIOE, &GPIO_InitStruct);

  /*Configure GPIO pins : STEP1_CTL_Pin STEP2_CTL_Pin USB_PWR_Pin */
  GPIO_InitStruct.Pin = STEP1_CTL_Pin|STEP2_CTL_Pin|USB_PWR_Pin;
  GPIO_InitStruct.Mode = GPIO_MODE_OUTPUT_PP;
  GPIO_InitStruct.Pull = GPIO_NOPULL;
  GPIO_InitStruct.Speed = GPIO_SPEED_FREQ_LOW;
  HAL_GPIO_Init(GPIOG, &GPIO_InitStruct);

  /*Configure GPIO pin : USB_OC_Pin */
  GPIO_InitStruct.Pin = USB_OC_Pin;
  GPIO_InitStruct.Mode = GPIO_MODE_INPUT;
  GPIO_InitStruct.Pull = GPIO_NOPULL;
  HAL_GPIO_Init(USB_OC_GPIO_Port, &GPIO_InitStruct);

  /*Configure GPIO pins : STEP1_EN_Pin STEP2_EN_Pin */
  GPIO_InitStruct.Pin = STEP1_EN_Pin|STEP2_EN_Pin;
  GPIO_InitStruct.Mode = GPIO_MODE_OUTPUT_PP;
  GPIO_InitStruct.Pull = GPIO_NOPULL;
  GPIO_InitStruct.Speed = GPIO_SPEED_FREQ_LOW;
  HAL_GPIO_Init(GPIOD, &GPIO_InitStruct);

  /* EXTI interrupt init*/
  HAL_NVIC_SetPriority(EXTI0_IRQn, 0, 0);
  HAL_NVIC_EnableIRQ(EXTI0_IRQn);

  HAL_NVIC_SetPriority(EXTI1_IRQn, 0, 0);
  HAL_NVIC_EnableIRQ(EXTI1_IRQn);

  HAL_NVIC_SetPriority(EXTI2_IRQn, 0, 0);
  HAL_NVIC_EnableIRQ(EXTI2_IRQn);

  HAL_NVIC_SetPriority(EXTI3_IRQn, 0, 0);
  HAL_NVIC_EnableIRQ(EXTI3_IRQn);

  HAL_NVIC_SetPriority(EXTI4_IRQn, 0, 0);
  HAL_NVIC_EnableIRQ(EXTI4_IRQn);

  HAL_NVIC_SetPriority(EXTI9_5_IRQn, 0, 0);
  HAL_NVIC_EnableIRQ(EXTI9_5_IRQn);

  HAL_NVIC_SetPriority(EXTI15_10_IRQn, 0, 0);
  HAL_NVIC_EnableIRQ(EXTI15_10_IRQn);

}

void Error_Handler(void)
{
}

/************************ (C) COPYRIGHT STMicroelectronics *****END OF FILE****/
